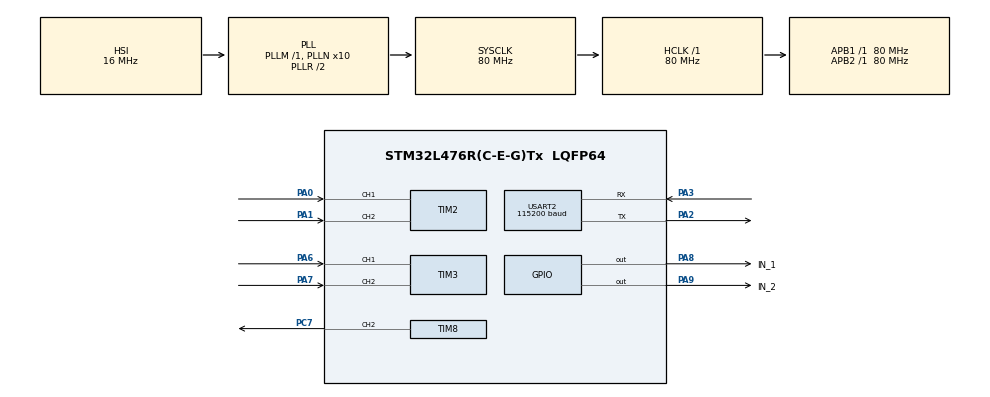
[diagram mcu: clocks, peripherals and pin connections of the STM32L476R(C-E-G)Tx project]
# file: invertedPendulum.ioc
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FREERTOS.Tasks01=controlAlgo,2,128,computeControlEffort,Default,NULL,Dynamic,NULL,NULL;sendMessage,-2,128,sendData,Default,NULL,Dynamic,NULL,NULL;safetyLimits,2,128,checkLimits,Default,NULL,Dynamic,NULL,NULL
Mcu.Family=STM32L4
Mcu.Name=STM32L476R(C-E-G)Tx
Mcu.Package=LQFP64
NVIC.PriorityGroup=NVIC_PRIORITYGROUP_4
NVIC.TIM2_IRQn=true\:5\:0\:false\:false\:true\:true\:true\:true\:true
NVIC.TIM3_IRQn=true\:5\:0\:false\:false\:true\:true\:true\:true\:true
NVIC.TIM6_DAC_IRQn=true\:15\:0\:false\:false\:true\:false\:false\:true\:true
NVIC.TimeBase=TIM6_DAC_IRQn
NVIC.TimeBaseIP=TIM6
NVIC.USART2_IRQn=true\:5\:0\:false\:false\:true\:true\:true\:true\:true
PA0.Signal=S_TIM2_CH1
PA1.Signal=S_TIM2_CH2
PA2.Mode=Asynchronous
PA2.Signal=USART2_TX
PA3.Mode=Asynchronous
PA3.Signal=USART2_RX
PA6.Signal=S_TIM3_CH1
PA7.Signal=S_TIM3_CH2
PA8.GPIO_Label=IN_1
PA8.Signal=GPIO_Output
PA9.GPIO_Label=IN_2
PA9.Signal=GPIO_Output
PC7.GPIO_PuPd=GPIO_PULLDOWN
PC7.Signal=S_TIM8_CH2
ProjectManager.HeapSize=0x200
ProjectManager.StackSize=0x400
ProjectManager.TargetToolchain=STM32CubeIDE
RCC.ADCFreq_Value=64000000
RCC.AHBFreq_Value=80000000
RCC.APB1Freq_Value=80000000
RCC.APB1TimFreq_Value=80000000
RCC.APB2Freq_Value=80000000
RCC.APB2TimFreq_Value=80000000
RCC.CortexFreq_Value=80000000
RCC.HCLKFreq_Value=80000000
RCC.HSE_VALUE=8000000
RCC.HSI_VALUE=16000000
RCC.LSE_VALUE=32768
RCC.MSI_VALUE=4000000
RCC.PLLN=10
RCC.PLLSourceVirtual=RCC_PLLSOURCE_HSI
RCC.PREFETCH_ENABLE=1
RCC.SYSCLKFreq_VALUE=80000000
RCC.SYSCLKSource=RCC_SYSCLKSOURCE_PLLCLK
RCC.USBFreq_Value=64000000
RCC.VCOOutputFreq_Value=160000000
SH.S_TIM2_CH1.0=TIM2_CH1,Encoder_Interface
SH.S_TIM2_CH2.0=TIM2_CH2,Encoder_Interface
SH.S_TIM3_CH1.0=TIM3_CH1,Encoder_Interface
SH.S_TIM3_CH2.0=TIM3_CH2,Encoder_Interface
SH.S_TIM8_CH2.0=TIM8_CH2,PWM Generation2 CH2
TIM2.AutoReloadPreload=TIM_AUTORELOAD_PRELOAD_ENABLE
TIM2.EncoderMode=TIM_ENCODERMODE_TI12
TIM3.AutoReloadPreload=TIM_AUTORELOAD_PRELOAD_ENABLE
TIM3.EncoderMode=TIM_ENCODERMODE_TI12
TIM8.AutoReloadPreload=TIM_AUTORELOAD_PRELOAD_ENABLE
TIM8.BreakPolarity=TIM_BREAKPOLARITY_HIGH
TIM8.Channel-PWM\ Generation2\ CH2=TIM_CHANNEL_2
TIM8.Period=10000
USART2.BaudRate=115200
USART2.VirtualMode-Asynchronous=VM_ASYNC
VP_FREERTOS_VS_CMSIS_V1.Mode=CMSIS_V1
VP_SYS_VS_tim6.Mode=TIM6
VP_TIM8_VS_ClockSourceINT.Mode=Internal
board=NUCLEO-L476RG

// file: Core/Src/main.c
/* USER CODE BEGIN Header */
/**
  ******************************************************************************
  * @file           : main.c
  * @brief          : Main program body
  ******************************************************************************
  * @attention
  *
  * Copyright (c) 2023 STMicroelectronics.
  * All rights reserved.
  *
  * This software is licensed under terms that can be found in the LICENSE file
  * in the root directory of this software component.
  * If no LICENSE file comes with this software, it is provided AS-IS.
  *
  ******************************************************************************
  */
/* USER CODE END Header */
#include "main.h"
#include "cmsis_os.h"

/* USER CODE BEGIN Includes */
#include <stdio.h>
#include <stdlib.h>
#include <pendulum.h>
#include <string.h>
/* USER CODE END Includes */

/* USER CODE BEGIN PTD */
#define MAX_COUNTER_VALUE 65535
#define STEPS_TO_DEG 0.04394531

/* USER CODE END PTD */

TIM_HandleTypeDef htim2;
TIM_HandleTypeDef htim3;
TIM_HandleTypeDef htim8;

UART_HandleTypeDef huart2;

osThreadId controlAlgoHandle;
osThreadId sendMessageHandle;
osThreadId safetyLimitsHandle;
/* USER CODE BEGIN PV */
SemaphoreHandle_t threadLock;
PID_Controller pend_controller, arm_controller;
uint32_t counter = 0;
uint32_t previousCounterArm = 0;
uint32_t previousCounterPend = 0;
int32_t netPositionPend = 0;
int32_t netPositionArm = 0;
uint8_t disturbance_threshold = 0;
double pendPrevPos;
double pendCurrVel;
double armPrevPos;
double armCurrVel;

uint8_t posOffsetFlag = 0;
uint8_t swingDownFlag = 0;
uint8_t velCount = 0;
uint8_t swingUpFlag = 0;
uint8_t balanceState = 0;
uint8_t paramStringFlag = 0;
int P1t, I1t, D1t, P2t, I2t, D2t, dzt, voltageLim;
char rx_buffer[MAX_MSG_LENGTH];
uint8_t rx_data;
int rx_index = 0;
uint32_t swingUpCount = 0;
uint32_t swingDownCount = 0;

/* USER CODE END PV */

void SystemClock_Config(void);
static void MX_GPIO_Init(void);
static void MX_TIM8_Init(void);
static void MX_TIM2_Init(void);
static void MX_TIM3_Init(void);
static void MX_USART2_UART_Init(void);
void computeControlEffort(void const * argument);
void sendData(void const * argument);
void checkLimits(void const * argument);

/* USER CODE BEGIN PFP */
void updatePosition(uint32_t currentCounter, uint32_t *prevCounter, int32_t *net);
void swingUpPendulum();
void swingDownPendulum();
void checkFallDirection();
void updatePendulumState(uint32_t armEncoder, uint32_t pendEncoder);
void balanceControl();
void swingUpControl();
double calculateVelocity(double *currPos, double *prevPos, double period);
void swingDownControl();

/* USER CODE END PFP */

/* USER CODE BEGIN 0 */

void updatePosition(uint32_t currentCounter, uint32_t *prevCounter, int32_t *net) {
    // Calculate the change in counter value since the last callback
    int32_t counterChange = currentCounter - *prevCounter;

    // Update the previous counter value for the next iteration
    *prevCounter = currentCounter;

    // Handle wrap-around by checking if the change is larger than half the range
    if (counterChange > MAX_COUNTER_VALUE / 2) {
        counterChange -= MAX_COUNTER_VALUE + 1;  // Handle wrap from high to low
    } else if (counterChange < -MAX_COUNTER_VALUE / 2) {
        counterChange += MAX_COUNTER_VALUE + 1;  // Handle wrap from low to high
    }

    // Update the net position
    *net += counterChange;
}

void updatePendulumState(uint32_t armEncoder, uint32_t pendEncoder){

	// Read current pendulum position state (in encoder pulses)
	updatePosition(armEncoder, &previousCounterArm, &netPositionArm);
	updatePosition(pendEncoder, &previousCounterPend, &netPositionPend);

	// Updates pendulum & arm position in degrees from encoder readings
	armCurrPos = netPositionArm*STEPS_TO_DEG;
	pendCurrPos = -1*netPositionPend*STEPS_TO_DEG;

	if(!swingUpFlag) {
		pendSetPoint = *arm_controller.Output;
	}
}

void swingUpPendulum() {

	if(balanceState) {
		return;
	}

	disturbance_threshold = SWINGUP_THRESH;
	netPositionPend = 180.0/STEPS_TO_DEG;
	Controller_SetOutputLimits(&arm_controller, -VOLTAGE_LIMIT_SWINGUP, VOLTAGE_LIMIT_SWINGUP);
	Controller_SetTunings(&arm_controller, 2, 0.15, 0.045);
	arm_controller.OutputSum = 0.00;
	armSetPoint = armCurrPos + SWINGUP_SETPOINT + SWINGUP_MULTIPLIER*armCurrPos;
	swingUpFlag = 1;
	balanceState = 1;
}

double calculateVelocity(double *currPos, double *prevPos, double period) {
	double vel = (*currPos - *prevPos)/(period/1000.0);
	return vel;
}

void swingDownPendulum() {

	swingUpFlag = 0;
	posOffsetFlag = 1;
	swingDownFlag = 1;
	armSetPoint = 0;
	Controller_SetTunings(&arm_controller, 0.45, 0.1, 0.15);
	Controller_SetTunings(&pend_controller, 0.8, 0, 0.01);
}

void swingDownControl() {

	// Update control output
	updateControllers(&pend_controller, &arm_controller);

	double outVoltage = *pend_controller.Output;

	// Set Motor Direction
	if(outVoltage > 0)
	{

		HAL_GPIO_WritePin(GPIOA, IN_1_Pin, GPIO_PIN_SET);
		HAL_GPIO_WritePin(GPIOA, IN_2_Pin, GPIO_PIN_RESET);
	}

	else
	{
		HAL_GPIO_WritePin(GPIOA, IN_1_Pin, GPIO_PIN_RESET);
		HAL_GPIO_WritePin(GPIOA, IN_2_Pin, GPIO_PIN_SET);
	}

	// Calculate PWM counter for given voltage
	int dutyCycle = (abs(outVoltage) + dz)* MAX_PWM / MAX_MOTOR_VOLTAGE;

	// Set Motor PWM Cycle
	__HAL_TIM_SET_COMPARE(&htim8, TIM_CHANNEL_2, dutyCycle);

}

void checkFallDirection() {

	if(abs(pendCurrPos) > MAX_DISTURBANCE){
		netPositionPend += 180/STEPS_TO_DEG*(pendCurrPos)/abs(pendCurrPos);
		balanceState = 0;
	}
}

void swingUpControl() {

	// Update control output
	updateControllers(&pend_controller, &arm_controller);

	double outVoltage = *arm_controller.Output;

	// Set Motor Direction
	if(outVoltage > 0)
	{

		HAL_GPIO_WritePin(GPIOA, IN_1_Pin, GPIO_PIN_SET);
		HAL_GPIO_WritePin(GPIOA, IN_2_Pin, GPIO_PIN_RESET);
	}

	else
	{
		HAL_GPIO_WritePin(GPIOA, IN_1_Pin, GPIO_PIN_RESET);
		HAL_GPIO_WritePin(GPIOA, IN_2_Pin, GPIO_PIN_SET);
	}

	// Calculate PWM counter for given voltage
	int dutyCycle = (abs(outVoltage) + dz)* MAX_PWM / MAX_MOTOR_VOLTAGE;

	// Set Motor PWM Cycle
	__HAL_TIM_SET_COMPARE(&htim8, TIM_CHANNEL_2, dutyCycle);
}

void balanceControl() {

	// Update Pendulum Control Output
	updateControllers(&pend_controller, &arm_controller);

	double outVoltage = *pend_controller.Output;

	// Set Motor Direction
	if(outVoltage < 0)
	{

		HAL_GPIO_WritePin(GPIOA, IN_1_Pin, GPIO_PIN_SET);
		HAL_GPIO_WritePin(GPIOA, IN_2_Pin, GPIO_PIN_RESET);
	}

	else
	{
		HAL_GPIO_WritePin(GPIOA, IN_1_Pin, GPIO_PIN_RESET);
		HAL_GPIO_WritePin(GPIOA, IN_2_Pin, GPIO_PIN_SET);
	}

	// Calculate PWM counter for given voltage
	int dutyCycle = (abs(outVoltage) + dz)* MAX_PWM / MAX_MOTOR_VOLTAGE;

	// Set Motor PWM Cycle
	__HAL_TIM_SET_COMPARE(&htim8, TIM_CHANNEL_2, dutyCycle);
}

/* USER CODE END 0 */

int main(void)
{

  /* MCU Configuration--------------------------------------------------------*/

  /* Reset of all peripherals, Initializes the Flash interface and the Systick. */
  HAL_Init();

  /* USER CODE BEGIN Init */

  /* Initialize PID Controllers for Pendulum angle and Motor Arm Angle */
  Controller_Init(&pend_controller, &pendCurrPos, &pendOutCmd, &pendSetPoint, P1, I1, D1, SAMPLE_PERIOD);
  Controller_Init(&arm_controller, &armCurrPos, &armOutCmd, &armSetPoint, P2, I2, D2, SAMPLE_PERIOD);

  /* Set Saturation Limits on Control Output */
  Controller_SetOutputLimits(&pend_controller, -VOLTAGE_LIMIT_BALANCE, VOLTAGE_LIMIT_BALANCE);
  Controller_SetOutputLimits(&arm_controller, -VOLTAGE_LIMIT_SWINGUP, VOLTAGE_LIMIT_SWINGUP);

  /* Initialize Variables */
  pendCurrPos = 180;
  pendPrevPos = pendCurrPos;
  armPrevPos = armCurrPos;
  pendOutCmd = 0;
  armCurrPos = 0;
  armOutCmd = 0;
  pendSetPoint = 0;
  armSetPoint = 0;

  /* USER CODE END Init */

  /* Configure the system clock */
  SystemClock_Config();

  /* Initialize all configured peripherals */
  MX_GPIO_Init();
  MX_TIM8_Init();
  MX_TIM2_Init();
  MX_TIM3_Init();
  MX_USART2_UART_Init();
  /* USER CODE BEGIN 2 */

  // Initialize UART Receive
  HAL_UART_Receive_IT(&huart2, &rx_data, 1);

  /* Start PWM for DC Motor and timers for encoders */
  HAL_TIM_PWM_Start(&htim8, TIM_CHANNEL_2);
  HAL_TIM_Encoder_Start(&htim2, TIM_CHANNEL_ALL);
  HAL_TIM_Encoder_Start(&htim3, TIM_CHANNEL_ALL);

  threadLock = xSemaphoreCreateMutex();
  if(threadLock == NULL) {
	  ;
  }

  /* USER CODE END 2 */

  /* Create the thread(s) */
  /* definition and creation of controlAlgo */
  osThreadDef(controlAlgo, computeControlEffort, osPriorityHigh, 0, 128);
  controlAlgoHandle = osThreadCreate(osThread(controlAlgo), NULL);

  /* definition and creation of sendMessage */
  osThreadDef(sendMessage, sendData, osPriorityLow, 0, 128);
  sendMessageHandle = osThreadCreate(osThread(sendMessage), NULL);

  /* definition and creation of safetyLimits */
  osThreadDef(safetyLimits, checkLimits, osPriorityHigh, 0, 128);
  safetyLimitsHandle = osThreadCreate(osThread(safetyLimits), NULL);

  // Illuminate status LED
  HAL_GPIO_WritePin(GPIOC, GPIO_PIN_10, GPIO_PIN_SET);

  /* Start scheduler */
  osKernelStart();

  /* We should never get here as control is now taken by the scheduler */
  /* Infinite loop */
  while (1)
  {

  }
}

void SystemClock_Config(void)
{
  RCC_OscInitTypeDef RCC_OscInitStruct = {0};
  RCC_ClkInitTypeDef RCC_ClkInitStruct = {0};

  /** Configure the main internal regulator output voltage
  */
  if (HAL_PWREx_ControlVoltageScaling(PWR_REGULATOR_VOLTAGE_SCALE1) != HAL_OK)
  {
    Error_Handler();
  }

  /** Initializes the RCC Oscillators according to the specified parameters
  * in the RCC_OscInitTypeDef structure.
  */
  RCC_OscInitStruct.OscillatorType = RCC_OSCILLATORTYPE_HSI;
  RCC_OscInitStruct.HSIState = RCC_HSI_ON;
  RCC_OscInitStruct.HSICalibrationValue = RCC_HSICALIBRATION_DEFAULT;
  RCC_OscInitStruct.PLL.PLLState = RCC_PLL_ON;
  RCC_OscInitStruct.PLL.PLLSource = RCC_PLLSOURCE_HSI;
  RCC_OscInitStruct.PLL.PLLM = 1;
  RCC_OscInitStruct.PLL.PLLN = 10;
  RCC_OscInitStruct.PLL.PLLP = RCC_PLLP_DIV7;
  RCC_OscInitStruct.PLL.PLLQ = RCC_PLLQ_DIV2;
  RCC_OscInitStruct.PLL.PLLR = RCC_PLLR_DIV2;
  if (HAL_RCC_OscConfig(&RCC_OscInitStruct) != HAL_OK)
  {
    Error_Handler();
  }

  /** Initializes the CPU, AHB and APB buses clocks
  */
  RCC_ClkInitStruct.ClockType = RCC_CLOCKTYPE_HCLK|RCC_CLOCKTYPE_SYSCLK
                              |RCC_CLOCKTYPE_PCLK1|RCC_CLOCKTYPE_PCLK2;
  RCC_ClkInitStruct.SYSCLKSource = RCC_SYSCLKSOURCE_PLLCLK;
  RCC_ClkInitStruct.AHBCLKDivider = RCC_SYSCLK_DIV1;
  RCC_ClkInitStruct.APB1CLKDivider = RCC_HCLK_DIV1;
  RCC_ClkInitStruct.APB2CLKDivider = RCC_HCLK_DIV1;

  if (HAL_RCC_ClockConfig(&RCC_ClkInitStruct, FLASH_LATENCY_4) != HAL_OK)
  {
    Error_Handler();
  }
}

static void MX_TIM2_Init(void)
{

  TIM_Encoder_InitTypeDef sConfig = {0};
  TIM_MasterConfigTypeDef sMasterConfig = {0};

  htim2.Instance = TIM2;
  htim2.Init.Prescaler = 0;
  htim2.Init.CounterMode = TIM_COUNTERMODE_UP;
  htim2.Init.Period = 4294967295;
  htim2.Init.ClockDivision = TIM_CLOCKDIVISION_DIV1;
  htim2.Init.AutoReloadPreload = TIM_AUTORELOAD_PRELOAD_ENABLE;
  sConfig.EncoderMode = TIM_ENCODERMODE_TI12;
  sConfig.IC1Polarity = TIM_ICPOLARITY_RISING;
  sConfig.IC1Selection = TIM_ICSELECTION_DIRECTTI;
  sConfig.IC1Prescaler = TIM_ICPSC_DIV1;
  sConfig.IC1Filter = 0;
  sConfig.IC2Polarity = TIM_ICPOLARITY_RISING;
  sConfig.IC2Selection = TIM_ICSELECTION_DIRECTTI;
  sConfig.IC2Prescaler = TIM_ICPSC_DIV1;
  sConfig.IC2Filter = 0;
  if (HAL_TIM_Encoder_Init(&htim2, &sConfig) != HAL_OK)
  {
    Error_Handler();
  }
  sMasterConfig.MasterOutputTrigger = TIM_TRGO_RESET;
  sMasterConfig.MasterSlaveMode = TIM_MASTERSLAVEMODE_DISABLE;
  if (HAL_TIMEx_MasterConfigSynchronization(&htim2, &sMasterConfig) != HAL_OK)
  {
    Error_Handler();
  }

}

static void MX_TIM3_Init(void)
{

  TIM_Encoder_InitTypeDef sConfig = {0};
  TIM_MasterConfigTypeDef sMasterConfig = {0};

  htim3.Instance = TIM3;
  htim3.Init.Prescaler = 0;
  htim3.Init.CounterMode = TIM_COUNTERMODE_UP;
  htim3.Init.Period = 65535;
  htim3.Init.ClockDivision = TIM_CLOCKDIVISION_DIV1;
  htim3.Init.AutoReloadPreload = TIM_AUTORELOAD_PRELOAD_ENABLE;
  sConfig.EncoderMode = TIM_ENCODERMODE_TI12;
  sConfig.IC1Polarity = TIM_ICPOLARITY_RISING;
  sConfig.IC1Selection = TIM_ICSELECTION_DIRECTTI;
  sConfig.IC1Prescaler = TIM_ICPSC_DIV1;
  sConfig.IC1Filter = 0;
  sConfig.IC2Polarity = TIM_ICPOLARITY_RISING;
  sConfig.IC2Selection = TIM_ICSELECTION_DIRECTTI;
  sConfig.IC2Prescaler = TIM_ICPSC_DIV1;
  sConfig.IC2Filter = 0;
  if (HAL_TIM_Encoder_Init(&htim3, &sConfig) != HAL_OK)
  {
    Error_Handler();
  }
  sMasterConfig.MasterOutputTrigger = TIM_TRGO_RESET;
  sMasterConfig.MasterSlaveMode = TIM_MASTERSLAVEMODE_DISABLE;
  if (HAL_TIMEx_MasterConfigSynchronization(&htim3, &sMasterConfig) != HAL_OK)
  {
    Error_Handler();
  }

}

static void MX_TIM8_Init(void)
{

  TIM_ClockConfigTypeDef sClockSourceConfig = {0};
  TIM_MasterConfigTypeDef sMasterConfig = {0};
  TIM_OC_InitTypeDef sConfigOC = {0};
  TIM_BreakDeadTimeConfigTypeDef sBreakDeadTimeConfig = {0};

  htim8.Instance = TIM8;
  htim8.Init.Prescaler = 0;
  htim8.Init.CounterMode = TIM_COUNTERMODE_UP;
  htim8.Init.Period = 10000;
  htim8.Init.ClockDivision = TIM_CLOCKDIVISION_DIV1;
  htim8.Init.RepetitionCounter = 0;
  htim8.Init.AutoReloadPreload = TIM_AUTORELOAD_PRELOAD_ENABLE;
  if (HAL_TIM_Base_Init(&htim8) != HAL_OK)
  {
    Error_Handler();
  }
  sClockSourceConfig.ClockSource = TIM_CLOCKSOURCE_INTERNAL;
  if (HAL_TIM_ConfigClockSource(&htim8, &sClockSourceConfig) != HAL_OK)
  {
    Error_Handler();
  }
  if (HAL_TIM_PWM_Init(&htim8) != HAL_OK)
  {
    Error_Handler();
  }
  sMasterConfig.MasterOutputTrigger = TIM_TRGO_RESET;
  sMasterConfig.MasterOutputTrigger2 = TIM_TRGO2_RESET;
  sMasterConfig.MasterSlaveMode = TIM_MASTERSLAVEMODE_DISABLE;
  if (HAL_TIMEx_MasterConfigSynchronization(&htim8, &sMasterConfig) != HAL_OK)
  {
    Error_Handler();
  }
  sConfigOC.OCMode = TIM_OCMODE_PWM1;
  sConfigOC.Pulse = 0;
  sConfigOC.OCPolarity = TIM_OCPOLARITY_HIGH;
  sConfigOC.OCNPolarity = TIM_OCNPOLARITY_HIGH;
  sConfigOC.OCFastMode = TIM_OCFAST_DISABLE;
  sConfigOC.OCIdleState = TIM_OCIDLESTATE_RESET;
  sConfigOC.OCNIdleState = TIM_OCNIDLESTATE_RESET;
  if (HAL_TIM_PWM_ConfigChannel(&htim8, &sConfigOC, TIM_CHANNEL_2) != HAL_OK)
  {
    Error_Handler();
  }
  sBreakDeadTimeConfig.OffStateRunMode = TIM_OSSR_DISABLE;
  sBreakDeadTimeConfig.OffStateIDLEMode = TIM_OSSI_DISABLE;
  sBreakDeadTimeConfig.LockLevel = TIM_LOCKLEVEL_OFF;
  sBreakDeadTimeConfig.DeadTime = 0;
  sBreakDeadTimeConfig.BreakState = TIM_BREAK_DISABLE;
  sBreakDeadTimeConfig.BreakPolarity = TIM_BREAKPOLARITY_HIGH;
  sBreakDeadTimeConfig.BreakFilter = 0;
  sBreakDeadTimeConfig.Break2State = TIM_BREAK2_DISABLE;
  sBreakDeadTimeConfig.Break2Polarity = TIM_BREAK2POLARITY_HIGH;
  sBreakDeadTimeConfig.Break2Filter = 0;
  sBreakDeadTimeConfig.AutomaticOutput = TIM_AUTOMATICOUTPUT_DISABLE;
  if (HAL_TIMEx_ConfigBreakDeadTime(&htim8, &sBreakDeadTimeConfig) != HAL_OK)
  {
    Error_Handler();
  }
  HAL_TIM_MspPostInit(&htim8);

}

static void MX_USART2_UART_Init(void)
{

  huart2.Instance = USART2;
  huart2.Init.BaudRate = 115200;
  huart2.Init.WordLength = UART_WORDLENGTH_8B;
  huart2.Init.StopBits = UART_STOPBITS_1;
  huart2.Init.Parity = UART_PARITY_NONE;
  huart2.Init.Mode = UART_MODE_TX_RX;
  huart2.Init.HwFlowCtl = UART_HWCONTROL_NONE;
  huart2.Init.OverSampling = UART_OVERSAMPLING_16;
  huart2.Init.OneBitSampling = UART_ONE_BIT_SAMPLE_DISABLE;
  huart2.AdvancedInit.AdvFeatureInit = UART_ADVFEATURE_NO_INIT;
  if (HAL_UART_Init(&huart2) != HAL_OK)
  {
    Error_Handler();
  }

}

static void MX_GPIO_Init(void)
{
  GPIO_InitTypeDef GPIO_InitStruct = {0};

  /* GPIO Ports Clock Enable */
  __HAL_RCC_GPIOA_CLK_ENABLE();
  __HAL_RCC_GPIOC_CLK_ENABLE();

  /* Configure GPIO pin Output Level */
  HAL_GPIO_WritePin(GPIOA, IN_1_Pin | IN_2_Pin, GPIO_PIN_RESET);

  /*Configure GPIO pins : IN_1_Pin IN_2_Pin */
  GPIO_InitStruct.Pin = IN_1_Pin | IN_2_Pin;
  GPIO_InitStruct.Mode = GPIO_MODE_OUTPUT_PP;
  GPIO_InitStruct.Pull = GPIO_NOPULL;
  GPIO_InitStruct.Speed = GPIO_SPEED_FREQ_LOW;
  HAL_GPIO_Init(GPIOA, &GPIO_InitStruct);

  /*Configure GPIO pin : PC10 */
  GPIO_InitStruct.Pin = GPIO_PIN_10;
  GPIO_InitStruct.Mode = GPIO_MODE_OUTPUT_PP;
  GPIO_InitStruct.Pull = GPIO_NOPULL;
  GPIO_InitStruct.Speed = GPIO_SPEED_FREQ_LOW;
  HAL_GPIO_Init(GPIOC, &GPIO_InitStruct);
}

/* USER CODE BEGIN 4 */

void HAL_UART_RxCpltCallback(UART_HandleTypeDef *huart)
{
    if (huart->Instance == USART2) // Adjust accordingly if using a different USART instance
    {

    	if(rx_data == 'P') {
    		paramStringFlag = 1;
    	}

    	if(paramStringFlag) {

    		// Z indicates end of parameter message string
    		if (rx_data == 'Z')
			{

				// Extract values from the received string
				sscanf(rx_buffer, "P%dA%dA%dA%dA%dA%dA%dA%dAZ",
					   &P1t, &I1t, &D1t, &P2t, &I2t, &D2t, &dzt, &voltageLim);

				printf("%s\n", rx_buffer);

				// divide dead zone;
				dz = dzt/1000.0;

				// Reset the buffer and index for the next message
				memset(rx_buffer, 0, sizeof(rx_buffer));
				rx_index = 0;

				if(!(swingUpFlag || swingDownFlag)) {
					Controller_SetTunings(&arm_controller, P2t/1000.0, I2t/1000.0, D2t/1000.0);
					Controller_SetTunings(&pend_controller, P1t/1000.0, I1t/1000.0, D1t/1000.0);
					Controller_SetOutputLimits(&pend_controller, -voltageLim, voltageLim);
				}

				paramStringFlag = 0;
			}

			else
			{
				// Add the received character to the buffer
				rx_buffer[rx_index++] = rx_data;

			}
    	}

    	// Swing up pendulum
    	else if(rx_data == 'U') {
    		swingUpPendulum();
    	}

    	// Swing down pendulum
    	else if(rx_data == 'D') {
    		swingDownPendulum();
    	}

    	else if(rx_data == 'Y') {
    		*arm_controller.Setpoint += 90;
    	}

    	else if(rx_data == 'J') {
    		*arm_controller.Setpoint -= 90;
    	}

    	// Enable UART to receive another byte
		HAL_UART_Receive_IT(&huart2, &rx_data, 1);
    }
}

/* USER CODE END 4 */

void computeControlEffort(void const * argument)
{
  /* USER CODE BEGIN 5 */

	for(;;)
	{

		// Refresh device position values
		updatePendulumState(TIM2->CNT, TIM3->CNT);

		// Calculate velocity of pendulum and motor
		if(velCount++ == VEL_SAMPLE_PERIOD){

			pendCurrVel = calculateVelocity(&pendCurrPos, &pendPrevPos, VEL_SAMPLE_PERIOD);
			armCurrVel = calculateVelocity(&armCurrPos, &armPrevPos, VEL_SAMPLE_PERIOD);

			// Update Pendulum Position
			pendPrevPos = pendCurrPos;
			armPrevPos = armCurrPos;

			// Reset velocity period counter
			velCount = 0;
		}

		// Swing up and balance is enabled
		if(balanceState) {

			// Swing up
			if(swingUpFlag) {
				swingUpControl();

				// Delay entering the balancing loop until the pendulum has started to move
				swingUpCount++;
			}

			//Balance pendulum
			if (swingUpCount > SWINGUP_DELAY && !swingDownFlag && ((abs(pendCurrPos) < disturbance_threshold) || ((abs(pendCurrVel) < VELOCITY_SWINGUP_THRESH || pendCurrPos > 0))))
			{
				// Reset flag once swing up is complete and update control parameters and disturbance threshold
				if(swingUpFlag)
				{
					swingUpFlag = 0;
					Controller_SetTunings(&arm_controller, P2t/1000.0, I2t/1000.0, D2t/1000.0);
					Controller_SetTunings(&pend_controller, P1t/1000.0, I1t/1000.0, D1t/1000.0);
					Controller_SetOutputLimits(&arm_controller, -ARM_CONTROL_LIMIT, ARM_CONTROL_LIMIT);
					disturbance_threshold = MAX_DISTURBANCE;
					armSetPoint = 0;
				}

				// Compute balancing control effort
				balanceControl();
			}

			else if(swingDownFlag) {

				if(swingDownCount++ < SWINGDOWN_DELAY) {
					HAL_GPIO_WritePin(GPIOA, IN_1_Pin, GPIO_PIN_RESET);
					HAL_GPIO_WritePin(GPIOA, IN_2_Pin, GPIO_PIN_SET);
					__HAL_TIM_SET_COMPARE(&htim8, TIM_CHANNEL_2, SWINGDOWN_INIT_DUTY);
				}

				else if(abs(pendCurrPos) > SWINGDOWN_THRESH || abs(armCurrPos) > SWINGDOWN_THRESH || abs(pendCurrVel) > VELOCITY_SWINGUP_THRESH || abs(armCurrVel) > VELOCITY_SWINGUP_THRESH){

					if(posOffsetFlag){
						// Refresh pendulum values
						updatePendulumState(TIM2->CNT, TIM3->CNT);

						// Adjust based on new set point in stable position
						netPositionPend += 180.0/STEPS_TO_DEG;

						// Halt the motor
						HAL_GPIO_WritePin(GPIOA, IN_1_Pin, GPIO_PIN_RESET);
						HAL_GPIO_WritePin(GPIOA, IN_2_Pin, GPIO_PIN_RESET);

						// Reset position offset flag
						posOffsetFlag = 0;
					}

					// Don't begin active swing down controller until pendulum has naturally fallen below the midway point
					else if(abs(pendCurrPos) < SWINGDOWN_BEGIN_ANGLE) {
						swingDownControl();
					}
				}

				// Pendulum is still in stable position, reset swing down flags and indicate that the pendulum is not balancing
				else {
					swingDownFlag = 0;
					balanceState = 0;
					swingDownCount = 0;
					swingUpCount = 0;
				}
			}

			else if(!swingUpFlag){
				// Reset balance flag to indicate pendulum is not balancing
				balanceState = 0;
				checkFallDirection();

			}
		}

		else {
			// Brake Motor if outside of balancing range
			HAL_GPIO_WritePin(GPIOA, IN_1_Pin, GPIO_PIN_RESET);
			HAL_GPIO_WritePin(GPIOA, IN_2_Pin, GPIO_PIN_RESET);
		}

		// Thread sleep for sample time
		osDelay(SAMPLE_PERIOD);

	}
  /* USER CODE END 5 */
}

void sendData(void const * argument)
{
  /* USER CODE BEGIN sendData */
  /* Infinite loop */
  for(;;)
  {
	  char tx_buf[30];

	  // Convert angles to string with two decimal places
	  sprintf(tx_buf, "%ldA%ldZ\n\r", netPositionArm, -1*netPositionPend);

	  // Transmit the string via UART
	  HAL_UART_Transmit(&huart2, (uint8_t*)tx_buf, strlen(tx_buf), 100);

      osDelay(20);
  }
  /* USER CODE END sendData */
}

void checkLimits(void const * argument)
{
  /* USER CODE BEGIN checkLimits */
  /* Infinite loop */
  for(;;)
  {
    osDelay(SAMPLE_PERIOD);

    // Shut down main motor if pendulum passes through physical limits
    if(abs(armCurrPos) > DEVICE_LIMIT) {
		HAL_GPIO_WritePin(GPIOA, IN_1_Pin, GPIO_PIN_RESET);
		HAL_GPIO_WritePin(GPIOA, IN_2_Pin, GPIO_PIN_RESET);
		balanceState = 0;
		swingUpFlag = 0;
		swingDownFlag = 0;
		swingUpCount = 0;
		swingDownCount = 0;
    }
  }
  /* USER CODE END checkLimits */
}

void HAL_TIM_PeriodElapsedCallback(TIM_HandleTypeDef *htim)
{
  if (htim->Instance == TIM6) {
    HAL_IncTick();
  }
}

void Error_Handler(void)
{
  __disable_irq();
  while (1)
  {
  }
}
